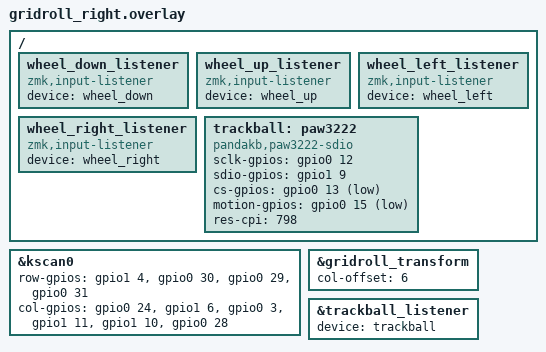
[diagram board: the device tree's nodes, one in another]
// SPDX-License-Identifier: MIT
#include "gridroll.dtsi"
&kscan0 {
    row-gpios = <&gpio1 4 (GPIO_ACTIVE_HIGH | GPIO_PULL_DOWN)>,
        <&gpio0 30 (GPIO_ACTIVE_HIGH | GPIO_PULL_DOWN)>,
        <&gpio0 29 (GPIO_ACTIVE_HIGH | GPIO_PULL_DOWN)>,
        <&gpio0 31 (GPIO_ACTIVE_HIGH | GPIO_PULL_DOWN)>;
    col-gpios = <&gpio0 24 GPIO_ACTIVE_HIGH>,
        <&gpio1 6 GPIO_ACTIVE_HIGH>,
        <&gpio0 3 GPIO_ACTIVE_HIGH>,
        <&gpio1 11 GPIO_ACTIVE_HIGH>,
        <&gpio1 10 GPIO_ACTIVE_HIGH>,
        <&gpio0 28 GPIO_ACTIVE_HIGH>;
};
&gridroll_transform { col-offset = <6>; };

/ {
    wheel_down_listener { compatible = "zmk,input-listener"; device = <&wheel_down>; };
    wheel_up_listener { compatible = "zmk,input-listener"; device = <&wheel_up>; };
    wheel_left_listener { compatible = "zmk,input-listener"; device = <&wheel_left>; };
    wheel_right_listener { compatible = "zmk,input-listener"; device = <&wheel_right>; };
    trackball: paw3222 {
        compatible = "pandakb,paw3222-sdio";
        sclk-gpios = <&gpio0 12 GPIO_ACTIVE_HIGH>;
        sdio-gpios = <&gpio1 9 GPIO_ACTIVE_HIGH>;
        cs-gpios = <&gpio0 13 GPIO_ACTIVE_LOW>;
        motion-gpios = <&gpio0 15 (GPIO_ACTIVE_LOW | GPIO_PULL_UP)>;
        res-cpi = <798>; // Native 38-CPI step: closest setting to 800 DPI.
        status = "okay";
    };
};
&trackball_listener { status = "okay"; device = <&trackball>; };

